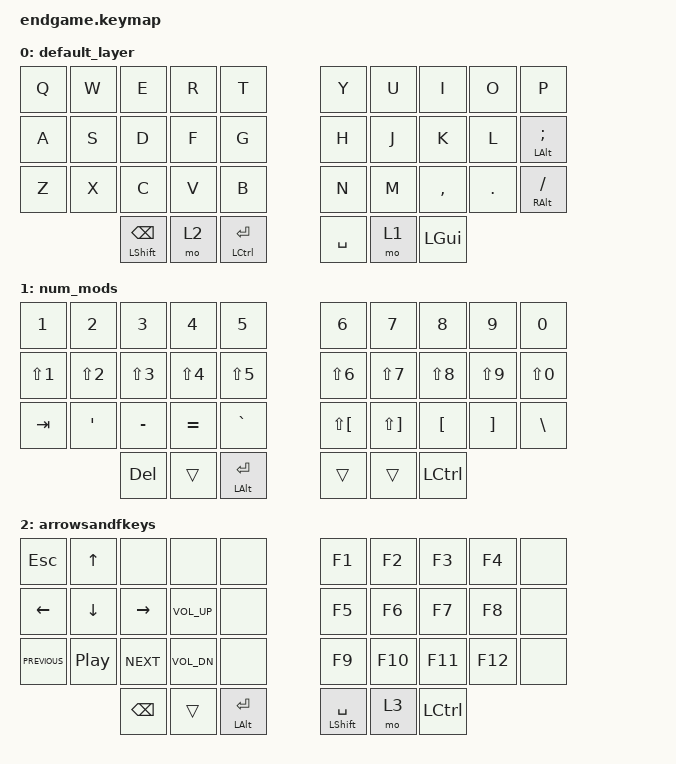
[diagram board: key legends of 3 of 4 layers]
/*
 * Copyright (c) 2021 The ZMK Contributors
 *
 * SPDX-License-Identifier: MIT
 */

#include <behaviors.dtsi>
#include <dt-bindings/zmk/bt.h>
#include <dt-bindings/zmk/keys.h>

#define DEFAULT  0
#define NUM_MODS 1
#define BT_CTRL  2

&mt {
    tapping-term-ms = <250>;
    flavor = "tap-preferred";
};

/ {
    keymap {
        compatible = "zmk,keymap";

        default_layer {
            bindings = <
&kp Q                 &kp W  &kp E            &kp R      &kp T  &kp Y     &kp U  &kp I      &kp O    &kp P
&kp A                 &kp S  &kp D            &kp F      &kp G  &kp H     &kp J  &kp K      &kp L    &mt LEFT_ALT SEMICOLON
&kp Z                 &kp X  &kp C            &kp V      &kp B  &kp N     &kp M  &kp COMMA  &kp DOT  &mt RIGHT_ALT SLASH
&mt LSHIFT BACKSPACE  &mo 2  &mt LCTRL ENTER  &kp SPACE  &mo 1  &kp LGUI
            >;
        };

        num_mods {
            bindings = <
&kp NUMBER_1  &kp NUMBER_2  &kp NUMBER_3        &kp NUMBER_4  &kp N5      &kp NUMBER_6  &kp N7        &kp N8      &kp N9      &kp N0
&kp LS(N1)    &kp LS(N2)    &kp LS(N3)          &kp LS(N4)    &kp LS(N5)  &kp LS(N6)    &kp LS(N7)    &kp LS(N8)  &kp LS(N9)  &kp LS(N0)
&kp TAB       &kp APOS      &kp MINUS           &kp EQUAL     &kp GRAVE   &kp LS(LBKT)  &kp LS(RBKT)  &kp LBKT    &kp RBKT    &kp BSLH
&kp DELETE    &trans        &mt LEFT_ALT ENTER  &trans        &trans      &kp LCTRL
            >;
        };

        arrowsandfkeys {
            bindings = <
&kp ESCAPE      &kp UP_ARROW      &none               &none             &none  &kp F1     &kp F2   &kp F3   &kp F4   &none
&kp LEFT        &kp DOWN_ARROW    &kp RIGHT           &kp C_VOLUME_UP   &none  &kp F5     &kp F6   &kp F7   &kp F8   &none
&kp C_PREVIOUS  &kp C_PLAY_PAUSE  &kp C_NEXT          &kp C_VOL_DN      &none  &kp F9     &kp F10  &kp F11  &kp F12  &none
&kp BACKSPACE   &trans            &mt LEFT_ALT ENTER  &mt LSHIFT SPACE  &mo 3  &kp LCTRL
            >;
        };

        btcontrol {
            bindings = <
&bt BT_SEL 0  &bt BT_SEL 1  &bt BT_SEL 2  &bt BT_SEL 3  &bt BT_SEL 4  &bt BT_CLR  &bt BT_CLR_ALL  &trans  &trans  &sys_reset
&trans        &trans        &trans        &trans        &trans        &trans      &trans          &trans  &trans  &bootloader
&trans        &trans        &trans        &trans        &trans        &trans      &trans          &trans  &trans  &trans
&trans        &trans        &trans        &trans        &trans        &trans      &trans          &trans  &trans  &trans
            >;
        };
    };
};
